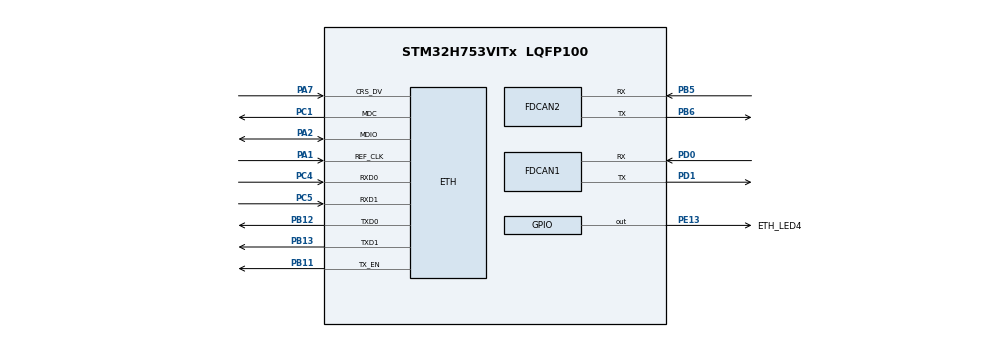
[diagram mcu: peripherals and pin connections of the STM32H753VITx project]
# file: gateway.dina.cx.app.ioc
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CORTEX_M7.AccessPermission-Cortex_Memory_Protection_Unit_Region0_Settings=MPU_REGION_FULL_ACCESS
CORTEX_M7.AccessPermission-Cortex_Memory_Protection_Unit_Region1_Settings=MPU_REGION_FULL_ACCESS
CORTEX_M7.BaseAddress-Cortex_Memory_Protection_Unit_Region0_Settings=0x30040000
CORTEX_M7.BaseAddress-Cortex_Memory_Protection_Unit_Region1_Settings=0x30040000
CORTEX_M7.CPU_DCache=Enabled
CORTEX_M7.CPU_ICache=Enabled
CORTEX_M7.DisableExec-Cortex_Memory_Protection_Unit_Region1_Settings=MPU_INSTRUCTION_ACCESS_DISABLE
CORTEX_M7.Enable-Cortex_Memory_Protection_Unit_Region0_Settings=MPU_REGION_ENABLE
CORTEX_M7.Enable-Cortex_Memory_Protection_Unit_Region1_Settings=MPU_REGION_ENABLE
CORTEX_M7.IsBufferable-Cortex_Memory_Protection_Unit_Region1_Settings=MPU_ACCESS_BUFFERABLE
CORTEX_M7.IsCacheable-Cortex_Memory_Protection_Unit_Region1_Settings=MPU_ACCESS_NOT_CACHEABLE
CORTEX_M7.IsShareable-Cortex_Memory_Protection_Unit_Region1_Settings=MPU_ACCESS_SHAREABLE
CORTEX_M7.MPU_Control=MPU_PRIVILEGED_DEFAULT
CORTEX_M7.Size-Cortex_Memory_Protection_Unit_Region0_Settings=MPU_REGION_SIZE_32KB
CORTEX_M7.Size-Cortex_Memory_Protection_Unit_Region1_Settings=MPU_REGION_SIZE_256B
CORTEX_M7.TypeExtField-Cortex_Memory_Protection_Unit_Region0_Settings=MPU_TEX_LEVEL1
ETH.MediaInterface=HAL_ETH_RMII_MODE
ETH.RxDescAddress=0x30040000
ETH.TxDescAddress=0x30040060
FDCAN1.AutoRetransmission=DISABLE
FDCAN1.CalculateBaudRateNominal=125000
FDCAN1.CalculateTimeBitNominal=8000
FDCAN1.CalculateTimeQuantumNominal=500.0
FDCAN1.ClockCalibrationCCU=DISABLE
FDCAN1.DataPrescaler=25
FDCAN1.DataSyncJumpWidth=1
FDCAN1.DataTimeSeg1=13
FDCAN1.DataTimeSeg2=2
FDCAN1.FrameFormat=FDCAN_FRAME_CLASSIC
FDCAN1.Mode=FDCAN_MODE_NORMAL
FDCAN1.NominalPrescaler=25
FDCAN1.NominalSyncJumpWidth=1
FDCAN1.NominalTimeSeg1=6
FDCAN1.NominalTimeSeg2=9
FDCAN1.RxFifo0ElmtsNbr=2
FDCAN1.StdFiltersNbr=1
FDCAN1.TransmitPause=DISABLE
FDCAN1.TxBuffersNbr=0
FDCAN1.TxFifoQueueElmtsNbr=1
FDCAN2.AutoRetransmission=DISABLE
FDCAN2.CalculateBaudRateNominal=125000
FDCAN2.CalculateTimeBitNominal=8000
FDCAN2.CalculateTimeQuantumNominal=500.0
FDCAN2.DataPrescaler=25
FDCAN2.DataSyncJumpWidth=1
FDCAN2.DataTimeSeg1=13
FDCAN2.DataTimeSeg2=2
FDCAN2.FrameFormat=FDCAN_FRAME_CLASSIC
FDCAN2.MessageRAMOffset=1280
FDCAN2.Mode=FDCAN_MODE_NORMAL
FDCAN2.NominalPrescaler=25
FDCAN2.NominalSyncJumpWidth=1
FDCAN2.NominalTimeSeg1=6
FDCAN2.NominalTimeSeg2=9
FDCAN2.RxFifo0ElmtsNbr=0
FDCAN2.RxFifo1ElmtsNbr=2
FDCAN2.StdFiltersNbr=1
FDCAN2.TransmitPause=DISABLE
FDCAN2.TxFifoQueueElmtsNbr=1
FREERTOS.Tasks01=lwipInitTask,24,256,startlwipInitTask,Default,NULL,Dynamic,NULL,NULL
FREERTOS.configMINIMAL_STACK_SIZE=256
FREERTOS.configUSE_NEWLIB_REENTRANT=1
LWIP.BSP.number=1
LWIP.GATEWAY_ADDRESS=192.168.100.001
LWIP.IP_ADDRESS=192.168.100.100
LWIP.LWIP_DHCP=0
LWIP.LWIP_HTTPD=1
LWIP.LWIP_HTTPD_CUSTOM_FILES=0
LWIP.LWIP_RAM_HEAP_POINTER=0x30044B00
LWIP.MEM_SIZE=10*1024
LWIP.NETMASK_ADDRESS=255.255.255.000
LWIP.Version=v2.1.2_Cube
LWIP0.BSP.STBoard=false
LWIP0.BSP.api=BSP_COMPONENT_DRIVER
LWIP0.BSP.component=LAN8742
LWIP0.BSP.instance=LAN8742
LWIP0.BSP.name=Driver_PHY
LWIP0.BSP.semaphore=S_LAN8742
LWIP0.BSP.solution=LAN8742
Mcu.Family=STM32H7
Mcu.Name=STM32H753VITx
Mcu.Package=LQFP100
NVIC.ETH_IRQn=true\:5\:0\:false\:false\:true\:true\:true\:true\:true
NVIC.FDCAN1_IT0_IRQn=true\:5\:0\:false\:false\:true\:true\:true\:true\:true
NVIC.FDCAN2_IT0_IRQn=true\:5\:0\:false\:false\:true\:true\:true\:true\:true
NVIC.PriorityGroup=NVIC_PRIORITYGROUP_4
NVIC.TIM6_DAC_IRQn=true\:15\:0\:false\:false\:true\:false\:false\:true\:true
NVIC.TimeBase=TIM6_DAC_IRQn
NVIC.TimeBaseIP=TIM6
PA1.GPIO_Speed=GPIO_SPEED_FREQ_VERY_HIGH
PA1.Mode=RMII
PA1.Signal=ETH_REF_CLK
PA2.GPIO_Speed=GPIO_SPEED_FREQ_VERY_HIGH
PA2.Mode=RMII
PA2.Signal=ETH_MDIO
PA7.GPIO_Speed=GPIO_SPEED_FREQ_VERY_HIGH
PA7.Mode=RMII
PA7.Signal=ETH_CRS_DV
PB11.GPIO_Speed=GPIO_SPEED_FREQ_VERY_HIGH
PB11.Mode=RMII
PB11.Signal=ETH_TX_EN
PB12.GPIO_Speed=GPIO_SPEED_FREQ_VERY_HIGH
PB12.Mode=RMII
PB12.Signal=ETH_TXD0
PB13.GPIO_Speed=GPIO_SPEED_FREQ_VERY_HIGH
PB13.Mode=RMII
PB13.Signal=ETH_TXD1
PB5.GPIO_PuPd=GPIO_PULLUP
PB5.GPIO_Speed=GPIO_SPEED_FREQ_VERY_HIGH
PB5.Mode=FDCAN_Activate
PB5.Signal=FDCAN2_RX
PB6.GPIO_PuPd=GPIO_PULLUP
PB6.GPIO_Speed=GPIO_SPEED_FREQ_VERY_HIGH
PB6.Mode=FDCAN_Activate
PB6.Signal=FDCAN2_TX
PC1.GPIO_Speed=GPIO_SPEED_FREQ_VERY_HIGH
PC1.Mode=RMII
PC1.Signal=ETH_MDC
PC4.GPIO_Speed=GPIO_SPEED_FREQ_VERY_HIGH
PC4.Mode=RMII
PC4.Signal=ETH_RXD0
PC5.GPIO_Speed=GPIO_SPEED_FREQ_VERY_HIGH
PC5.Mode=RMII
PC5.Signal=ETH_RXD1
PD0.GPIO_Mode=GPIO_MODE_AF_PP
PD0.GPIO_PuPd=GPIO_PULLUP
PD0.GPIO_Speed=GPIO_SPEED_FREQ_VERY_HIGH
PD0.Mode=FDCAN_Activate
PD0.Signal=FDCAN1_RX
PD1.GPIO_Mode=GPIO_MODE_AF_PP
PD1.GPIO_PuPd=GPIO_PULLUP
PD1.GPIO_Speed=GPIO_SPEED_FREQ_VERY_HIGH
PD1.Mode=FDCAN_Activate
PD1.Signal=FDCAN1_TX
PE13.GPIO_Label=ETH_LED4
PE13.Signal=GPIO_Output
PH0-OSC_IN\ (PH0).Mode=HSE-External-Oscillator
PH0-OSC_IN\ (PH0).Signal=RCC_OSC_IN
PH1-OSC_OUT\ (PH1).Mode=HSE-External-Oscillator
PH1-OSC_OUT\ (PH1).Signal=RCC_OSC_OUT
ProjectManager.HeapSize=0x200
ProjectManager.StackSize=0x400
ProjectManager.TargetToolchain=STM32CubeIDE
RCC.ADCFreq_Value=36000000
RCC.APB1Freq_Value=100000000
RCC.APB2Freq_Value=100000000
RCC.APB3Freq_Value=100000000
RCC.APB4Freq_Value=100000000
RCC.CortexFreq_Value=400000000
RCC.D1PPRE=RCC_APB3_DIV2
RCC.D2PPRE1=RCC_APB1_DIV2
RCC.D2PPRE2=RCC_APB2_DIV2
RCC.D3PPRE=RCC_APB4_DIV2
RCC.DIVM1=3
RCC.DIVM2=2
RCC.DIVN1=100
RCC.DIVN2=6
RCC.DIVQ1=16
RCC.DIVQ2=1
RCC.HCLKFreq_Value=200000000
RCC.HPRE=RCC_HCLK_DIV2
RCC.HSE_VALUE=24000000
RCC.PLLFRACN=0
RCC.PLLSourceVirtual=RCC_PLLSOURCE_HSE
RCC.SYSCLKFreq_VALUE=400000000
RCC.SYSCLKSource=RCC_SYSCLKSOURCE_PLLCLK
RCC.USBFreq_Value=50000000
VP_FREERTOS_VS_CMSIS_V2.Mode=CMSIS_V2
VP_LWIP_VS_Enabled.Mode=Enabled
VP_SYS_VS_tim6.Mode=TIM6
board=custom

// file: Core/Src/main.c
/* USER CODE BEGIN Header */
/**
  ******************************************************************************
  * @file           : main.c
  * @brief          : Main program body
  ******************************************************************************
  * @attention
  *
  * Copyright (c) 2022 STMicroelectronics.
  * All rights reserved.
  *
  * This software is licensed under terms that can be found in the LICENSE file
  * in the root directory of this software component.
  * If no LICENSE file comes with this software, it is provided AS-IS.
  *
  ******************************************************************************
  */
/* USER CODE END Header */
#include "main.h"
#include "cmsis_os.h"
#include "lwip.h"

/* USER CODE BEGIN Includes */
#include "lwip/udp.h"
#include "lwip/apps/httpd.h"
#include <string.h>
#include "../../Application/Common/typedefs.h"
#include "../../Application/Tasks/tasks_defs.h"
/* USER CODE END Includes */

FDCAN_HandleTypeDef hfdcan1;
FDCAN_HandleTypeDef hfdcan2;

/* Definitions for lwipInitTask */
osThreadId_t lwipInitTaskHandle;
const osThreadAttr_t lwipInitTask_attributes = {
  .name = "lwipInitTask",
  .stack_size = 256 * 4,
  .priority = (osPriority_t) osPriorityNormal,
};

void SystemClock_Config(void);
static void MPU_Config(void);
static void MX_GPIO_Init(void);
static void MX_FDCAN1_Init(void);
static void MX_FDCAN2_Init(void);
void startlwipInitTask(void *argument);

int main(void)
{

  /* MPU Configuration--------------------------------------------------------*/
  MPU_Config();

  /* Enable I-Cache---------------------------------------------------------*/
  SCB_EnableICache();

  /* Enable D-Cache---------------------------------------------------------*/
  SCB_EnableDCache();

  /* MCU Configuration--------------------------------------------------------*/

  /* Reset of all peripherals, Initializes the Flash interface and the Systick. */
  HAL_Init();

  /* Configure the system clock */
  SystemClock_Config();

  /* Initialize all configured peripherals */
  MX_GPIO_Init();
  MX_FDCAN1_Init();
  MX_FDCAN2_Init();

  /* Init scheduler */
  osKernelInitialize();

  /* Create the thread(s) */
  /* creation of lwipInitTask */
  lwipInitTaskHandle = osThreadNew(startlwipInitTask, NULL, &lwipInitTask_attributes);

  /* USER CODE BEGIN RTOS_THREADS */
  /* creation of dinaCxTask */
  dinaCxTaskHandle = osThreadNew(dinaCxTask, NULL, &dianCxTask_attributes);
  /* creation of can1Task */
  can1TaskHandle = osThreadNew(can1Task, NULL, &can1Task_attributes);
  /* creation of dinaCxTask */
  can2TaskHandle = osThreadNew(can2Task, NULL, &can2Task_attributes);
  /* USER CODE END RTOS_THREADS */

  /* Start scheduler */
  osKernelStart();

  /* We should never get here as control is now taken by the scheduler */
  /* Infinite loop */
  while (1)
  {

  }
}

void SystemClock_Config(void)
{
  RCC_OscInitTypeDef RCC_OscInitStruct = {0};
  RCC_ClkInitTypeDef RCC_ClkInitStruct = {0};

  /** Supply configuration update enable
  */
  HAL_PWREx_ConfigSupply(PWR_LDO_SUPPLY);

  /** Configure the main internal regulator output voltage
  */
  __HAL_PWR_VOLTAGESCALING_CONFIG(PWR_REGULATOR_VOLTAGE_SCALE1);

  while(!__HAL_PWR_GET_FLAG(PWR_FLAG_VOSRDY)) {}

  /** Initializes the RCC Oscillators according to the specified parameters
  * in the RCC_OscInitTypeDef structure.
  */
  RCC_OscInitStruct.OscillatorType = RCC_OSCILLATORTYPE_HSE;
  RCC_OscInitStruct.HSEState = RCC_HSE_ON;
  RCC_OscInitStruct.PLL.PLLState = RCC_PLL_ON;
  RCC_OscInitStruct.PLL.PLLSource = RCC_PLLSOURCE_HSE;
  RCC_OscInitStruct.PLL.PLLM = 3;
  RCC_OscInitStruct.PLL.PLLN = 100;
  RCC_OscInitStruct.PLL.PLLP = 2;
  RCC_OscInitStruct.PLL.PLLQ = 16;
  RCC_OscInitStruct.PLL.PLLR = 2;
  RCC_OscInitStruct.PLL.PLLRGE = RCC_PLL1VCIRANGE_3;
  RCC_OscInitStruct.PLL.PLLVCOSEL = RCC_PLL1VCOWIDE;
  RCC_OscInitStruct.PLL.PLLFRACN = 0;
  if (HAL_RCC_OscConfig(&RCC_OscInitStruct) != HAL_OK)
  {
    Error_Handler();
  }

  /** Initializes the CPU, AHB and APB buses clocks
  */
  RCC_ClkInitStruct.ClockType = RCC_CLOCKTYPE_HCLK|RCC_CLOCKTYPE_SYSCLK
                              |RCC_CLOCKTYPE_PCLK1|RCC_CLOCKTYPE_PCLK2
                              |RCC_CLOCKTYPE_D3PCLK1|RCC_CLOCKTYPE_D1PCLK1;
  RCC_ClkInitStruct.SYSCLKSource = RCC_SYSCLKSOURCE_PLLCLK;
  RCC_ClkInitStruct.SYSCLKDivider = RCC_SYSCLK_DIV1;
  RCC_ClkInitStruct.AHBCLKDivider = RCC_HCLK_DIV2;
  RCC_ClkInitStruct.APB3CLKDivider = RCC_APB3_DIV2;
  RCC_ClkInitStruct.APB1CLKDivider = RCC_APB1_DIV2;
  RCC_ClkInitStruct.APB2CLKDivider = RCC_APB2_DIV2;
  RCC_ClkInitStruct.APB4CLKDivider = RCC_APB4_DIV2;

  if (HAL_RCC_ClockConfig(&RCC_ClkInitStruct, FLASH_LATENCY_2) != HAL_OK)
  {
    Error_Handler();
  }
}

static void MX_FDCAN1_Init(void)
{

  hfdcan1.Instance = FDCAN1;
  hfdcan1.Init.FrameFormat = FDCAN_FRAME_CLASSIC;
  hfdcan1.Init.Mode = FDCAN_MODE_NORMAL;
  hfdcan1.Init.AutoRetransmission = DISABLE;
  hfdcan1.Init.TransmitPause = DISABLE;
  hfdcan1.Init.ProtocolException = DISABLE;
  hfdcan1.Init.NominalPrescaler = 25;
  hfdcan1.Init.NominalSyncJumpWidth = 1;
  hfdcan1.Init.NominalTimeSeg1 = 6;
  hfdcan1.Init.NominalTimeSeg2 = 9;
  hfdcan1.Init.DataPrescaler = 25;
  hfdcan1.Init.DataSyncJumpWidth = 1;
  hfdcan1.Init.DataTimeSeg1 = 13;
  hfdcan1.Init.DataTimeSeg2 = 2;
  hfdcan1.Init.MessageRAMOffset = 0;
  hfdcan1.Init.StdFiltersNbr = 1;
  hfdcan1.Init.ExtFiltersNbr = 0;
  hfdcan1.Init.RxFifo0ElmtsNbr = 2;
  hfdcan1.Init.RxFifo0ElmtSize = FDCAN_DATA_BYTES_8;
  hfdcan1.Init.RxFifo1ElmtsNbr = 0;
  hfdcan1.Init.RxFifo1ElmtSize = FDCAN_DATA_BYTES_8;
  hfdcan1.Init.RxBuffersNbr = 0;
  hfdcan1.Init.RxBufferSize = FDCAN_DATA_BYTES_8;
  hfdcan1.Init.TxEventsNbr = 0;
  hfdcan1.Init.TxBuffersNbr = 0;
  hfdcan1.Init.TxFifoQueueElmtsNbr = 1;
  hfdcan1.Init.TxFifoQueueMode = FDCAN_TX_FIFO_OPERATION;
  hfdcan1.Init.TxElmtSize = FDCAN_DATA_BYTES_8;
  if (HAL_FDCAN_Init(&hfdcan1) != HAL_OK)
  {
    Error_Handler();
  }

}

static void MX_FDCAN2_Init(void)
{

  hfdcan2.Instance = FDCAN2;
  hfdcan2.Init.FrameFormat = FDCAN_FRAME_CLASSIC;
  hfdcan2.Init.Mode = FDCAN_MODE_NORMAL;
  hfdcan2.Init.AutoRetransmission = DISABLE;
  hfdcan2.Init.TransmitPause = DISABLE;
  hfdcan2.Init.ProtocolException = DISABLE;
  hfdcan2.Init.NominalPrescaler = 25;
  hfdcan2.Init.NominalSyncJumpWidth = 1;
  hfdcan2.Init.NominalTimeSeg1 = 6;
  hfdcan2.Init.NominalTimeSeg2 = 9;
  hfdcan2.Init.DataPrescaler = 25;
  hfdcan2.Init.DataSyncJumpWidth = 1;
  hfdcan2.Init.DataTimeSeg1 = 13;
  hfdcan2.Init.DataTimeSeg2 = 2;
  hfdcan2.Init.MessageRAMOffset = 1280;
  hfdcan2.Init.StdFiltersNbr = 1;
  hfdcan2.Init.ExtFiltersNbr = 0;
  hfdcan2.Init.RxFifo0ElmtsNbr = 0;
  hfdcan2.Init.RxFifo0ElmtSize = FDCAN_DATA_BYTES_8;
  hfdcan2.Init.RxFifo1ElmtsNbr = 2;
  hfdcan2.Init.RxFifo1ElmtSize = FDCAN_DATA_BYTES_8;
  hfdcan2.Init.RxBuffersNbr = 0;
  hfdcan2.Init.RxBufferSize = FDCAN_DATA_BYTES_8;
  hfdcan2.Init.TxEventsNbr = 0;
  hfdcan2.Init.TxBuffersNbr = 0;
  hfdcan2.Init.TxFifoQueueElmtsNbr = 1;
  hfdcan2.Init.TxFifoQueueMode = FDCAN_TX_FIFO_OPERATION;
  hfdcan2.Init.TxElmtSize = FDCAN_DATA_BYTES_8;
  if (HAL_FDCAN_Init(&hfdcan2) != HAL_OK)
  {
    Error_Handler();
  }
  /* USER CODE BEGIN FDCAN2_Init 2 */

//  hfdcan2.Init.MessageRAMOffset = sizeof(hfdcan1);
//
//  if (HAL_FDCAN_Init(&hfdcan2) != HAL_OK)
//  {
//    Error_Handler();
//  }

  /* USER CODE END FDCAN2_Init 2 */

}

static void MX_GPIO_Init(void)
{
  GPIO_InitTypeDef GPIO_InitStruct = {0};

  /* GPIO Ports Clock Enable */
  __HAL_RCC_GPIOH_CLK_ENABLE();
  __HAL_RCC_GPIOC_CLK_ENABLE();
  __HAL_RCC_GPIOA_CLK_ENABLE();
  __HAL_RCC_GPIOE_CLK_ENABLE();
  __HAL_RCC_GPIOB_CLK_ENABLE();
  __HAL_RCC_GPIOD_CLK_ENABLE();

  /*Configure GPIO pin Output Level */
  HAL_GPIO_WritePin(ETH_LED4_GPIO_Port, ETH_LED4_Pin, GPIO_PIN_RESET);

  /*Configure GPIO pin : ETH_LED4_Pin */
  GPIO_InitStruct.Pin = ETH_LED4_Pin;
  GPIO_InitStruct.Mode = GPIO_MODE_OUTPUT_PP;
  GPIO_InitStruct.Pull = GPIO_NOPULL;
  GPIO_InitStruct.Speed = GPIO_SPEED_FREQ_LOW;
  HAL_GPIO_Init(ETH_LED4_GPIO_Port, &GPIO_InitStruct);

}

void startlwipInitTask(void *argument)
{
  /* init code for LWIP */
  MX_LWIP_Init();
  /* USER CODE BEGIN 5 */
  httpd_init();
  /* Infinite loop */
  for (;;)
  {
	  osDelay(5000);
  }
  /* USER CODE END 5 */
}

/* MPU Configuration */

void MPU_Config(void)
{
  MPU_Region_InitTypeDef MPU_InitStruct = {0};

  /* Disables the MPU */
  HAL_MPU_Disable();

  /** Initializes and configures the Region and the memory to be protected
  */
  MPU_InitStruct.Enable = MPU_REGION_ENABLE;
  MPU_InitStruct.Number = MPU_REGION_NUMBER0;
  MPU_InitStruct.BaseAddress = 0x30040000;
  MPU_InitStruct.Size = MPU_REGION_SIZE_32KB;
  MPU_InitStruct.SubRegionDisable = 0x0;
  MPU_InitStruct.TypeExtField = MPU_TEX_LEVEL1;
  MPU_InitStruct.AccessPermission = MPU_REGION_FULL_ACCESS;
  MPU_InitStruct.DisableExec = MPU_INSTRUCTION_ACCESS_ENABLE;
  MPU_InitStruct.IsShareable = MPU_ACCESS_NOT_SHAREABLE;
  MPU_InitStruct.IsCacheable = MPU_ACCESS_NOT_CACHEABLE;
  MPU_InitStruct.IsBufferable = MPU_ACCESS_NOT_BUFFERABLE;

  HAL_MPU_ConfigRegion(&MPU_InitStruct);

  /** Initializes and configures the Region and the memory to be protected
  */
  MPU_InitStruct.Number = MPU_REGION_NUMBER1;
  MPU_InitStruct.Size = MPU_REGION_SIZE_256B;
  MPU_InitStruct.TypeExtField = MPU_TEX_LEVEL0;
  MPU_InitStruct.DisableExec = MPU_INSTRUCTION_ACCESS_DISABLE;
  MPU_InitStruct.IsShareable = MPU_ACCESS_SHAREABLE;
  MPU_InitStruct.IsBufferable = MPU_ACCESS_BUFFERABLE;

  HAL_MPU_ConfigRegion(&MPU_InitStruct);
  /* Enables the MPU */
  HAL_MPU_Enable(MPU_PRIVILEGED_DEFAULT);

}

void HAL_TIM_PeriodElapsedCallback(TIM_HandleTypeDef *htim)
{
  if (htim->Instance == TIM6) {
    HAL_IncTick();
  }
}

void Error_Handler(void)
{
  __disable_irq();
  while (1)
  {
  }
}
